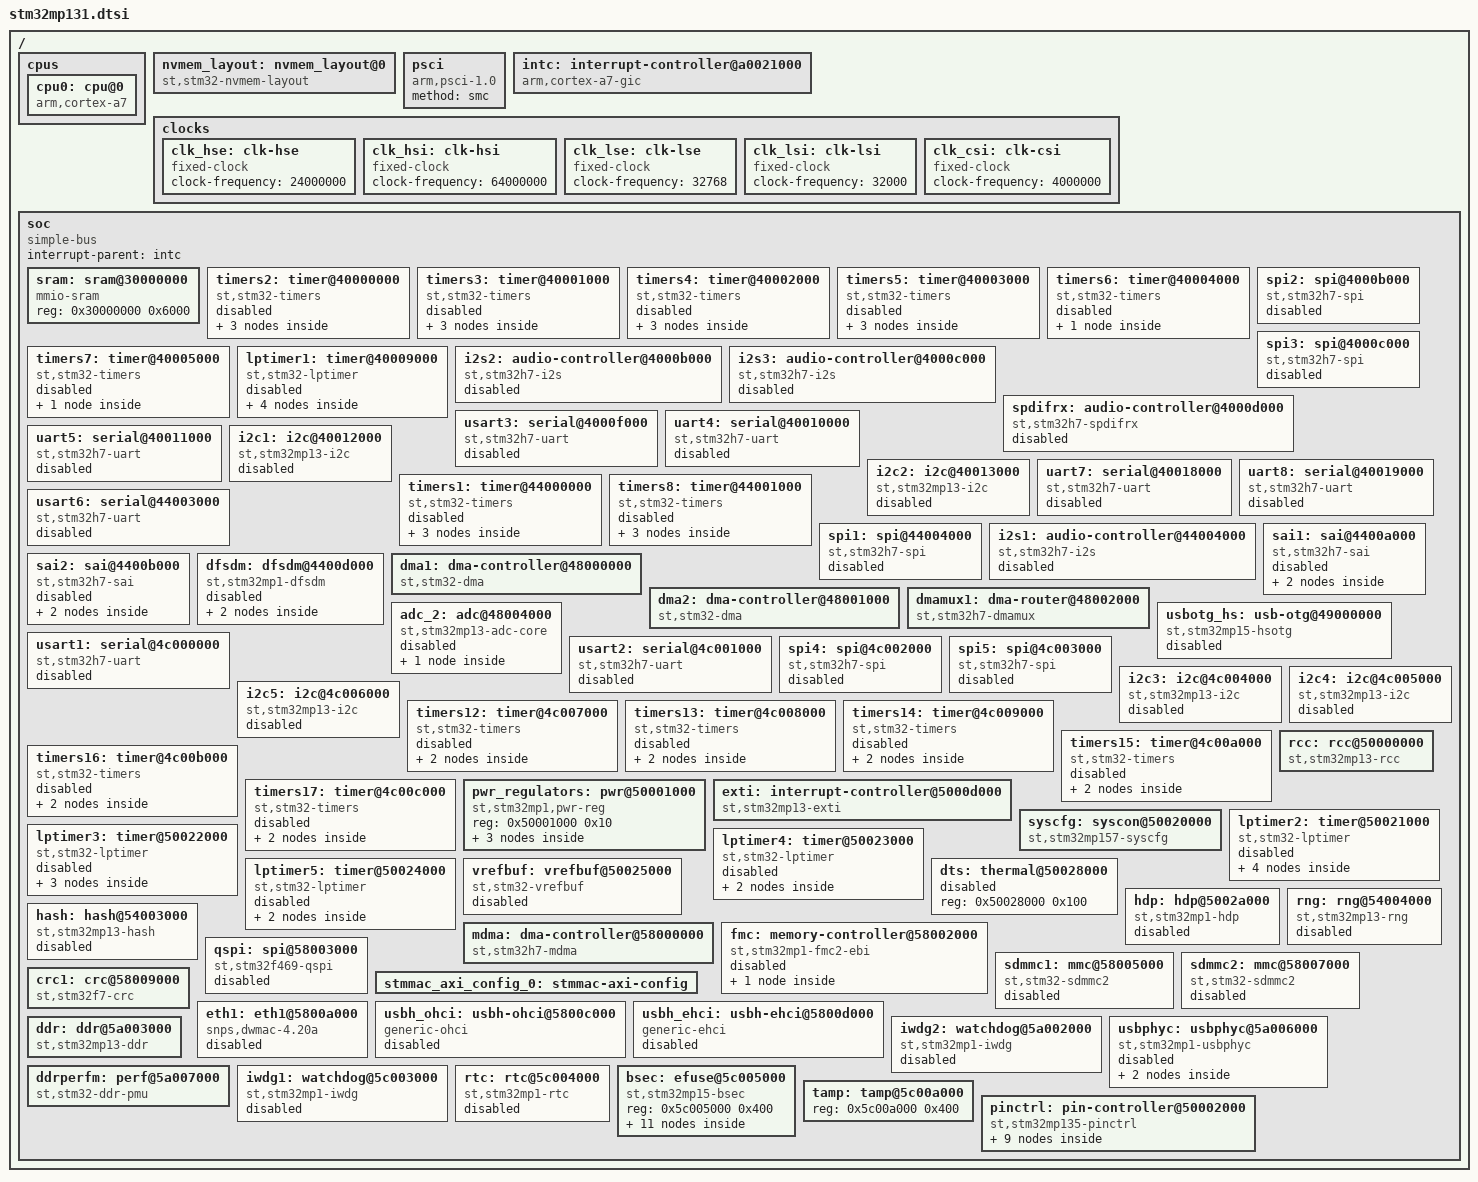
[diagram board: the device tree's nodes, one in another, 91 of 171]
// SPDX-License-Identifier: (GPL-2.0+ OR BSD-3-Clause)
/*
 * Copyright (C) STMicroelectronics 2017 - All Rights Reserved
 * Author: Ludovic Barre <ludovic.barre@st.com> for STMicroelectronics.
 */
#include <dt-bindings/interrupt-controller/arm-gic.h>
#include <dt-bindings/clock/stm32mp13-clks.h>
#include <dt-bindings/reset/stm32mp13-resets.h>

/ {
	#address-cells = <1>;
	#size-cells = <1>;

	cpus {
		#address-cells = <1>;
		#size-cells = <0>;

		cpu0: cpu@0 {
			compatible = "arm,cortex-a7";
			device_type = "cpu";
			reg = <0>;
			clocks = <&rcc CK_MPU>;
			clock-names = "cpu";
			nvmem-cells = <&part_number_otp>;
			nvmem-cell-names = "part_number";
		};
	};

	nvmem_layout: nvmem_layout@0 {
		compatible = "st,stm32-nvmem-layout";

		nvmem-cells = <&cfg0_otp>,
			      <&part_number_otp>,
			      <&monotonic_otp>,
			      <&nand_otp>,
			      <&nand2_otp>,
			      <&uid_otp>,
			      <&hw2_otp>,
			      <&pkh_otp>;

		nvmem-cell-names = "cfg0_otp",
				   "part_number_otp",
				   "monotonic_otp",
				   "nand_otp",
				   "nand2_otp",
				   "uid_otp",
				   "hw2_otp",
				   "pkh_otp";
	};

	psci {
		compatible = "arm,psci-1.0";
		method = "smc";
	};

	intc: interrupt-controller@a0021000 {
		compatible = "arm,cortex-a7-gic";
		#interrupt-cells = <3>;
		interrupt-controller;
		reg = <0xa0021000 0x1000>,
		      <0xa0022000 0x2000>;
	};

	clocks {
		clk_hse: clk-hse {
			#clock-cells = <0>;
			compatible = "fixed-clock";
			clock-frequency = <24000000>;
		};

		clk_hsi: clk-hsi {
			#clock-cells = <0>;
			compatible = "fixed-clock";
			clock-frequency = <64000000>;
		};

		clk_lse: clk-lse {
			#clock-cells = <0>;
			compatible = "fixed-clock";
			clock-frequency = <32768>;
		};

		clk_lsi: clk-lsi {
			#clock-cells = <0>;
			compatible = "fixed-clock";
			clock-frequency = <32000>;
		};

		clk_csi: clk-csi {
			#clock-cells = <0>;
			compatible = "fixed-clock";
			clock-frequency = <4000000>;
		};
	};

	soc {
		compatible = "simple-bus";
		#address-cells = <1>;
		#size-cells = <1>;
		interrupt-parent = <&intc>;
		ranges;

		sram: sram@30000000 {
			compatible = "mmio-sram";
			reg = <0x30000000 0x6000>;
			#address-cells = <1>;
			#size-cells = <1>;
			ranges = <0 0x30000000 0x6000>;
		};

		timers2: timer@40000000 {
			#address-cells = <1>;
			#size-cells = <0>;
			compatible = "st,stm32-timers";
			reg = <0x40000000 0x400>;
			interrupts = <GIC_SPI 29 IRQ_TYPE_LEVEL_HIGH>;
			clocks = <&rcc TIM2_K>;
			clock-names = "int";
			status = "disabled";

			pwm {
				compatible = "st,stm32-pwm";
				#pwm-cells = <3>;
				status = "disabled";
			};

			timer@1 {
				compatible = "st,stm32h7-timer-trigger";
				reg = <1>;
				status = "disabled";
			};

			counter {
				compatible = "st,stm32-timer-counter";
				status = "disabled";
			};
		};

		timers3: timer@40001000 {
			#address-cells = <1>;
			#size-cells = <0>;
			compatible = "st,stm32-timers";
			reg = <0x40001000 0x400>;
			interrupts = <GIC_SPI 30 IRQ_TYPE_LEVEL_HIGH>;
			clocks = <&rcc TIM3_K>;
			clock-names = "int";
			status = "disabled";

			pwm {
				compatible = "st,stm32-pwm";
				#pwm-cells = <3>;
				status = "disabled";
			};

			timer@2 {
				compatible = "st,stm32h7-timer-trigger";
				reg = <2>;
				status = "disabled";
			};

			counter {
				compatible = "st,stm32-timer-counter";
				status = "disabled";
			};
		};

		timers4: timer@40002000 {
			#address-cells = <1>;
			#size-cells = <0>;
			compatible = "st,stm32-timers";
			reg = <0x40002000 0x400>;
			interrupts = <GIC_SPI 31 IRQ_TYPE_LEVEL_HIGH>;
			clocks = <&rcc TIM4_K>;
			clock-names = "int";
			status = "disabled";

			pwm {
				compatible = "st,stm32-pwm";
				#pwm-cells = <3>;
				status = "disabled";
			};

			timer@3 {
				compatible = "st,stm32h7-timer-trigger";
				reg = <3>;
				status = "disabled";
			};

			counter {
				compatible = "st,stm32-timer-counter";
				status = "disabled";
			};
		};

		timers5: timer@40003000 {
			#address-cells = <1>;
			#size-cells = <0>;
			compatible = "st,stm32-timers";
			reg = <0x40003000 0x400>;
			interrupts = <GIC_SPI 51 IRQ_TYPE_LEVEL_HIGH>;
			clocks = <&rcc TIM5_K>;
			clock-names = "int";
			status = "disabled";

			pwm {
				compatible = "st,stm32-pwm";
				#pwm-cells = <3>;
				status = "disabled";
			};

			timer@4 {
				compatible = "st,stm32h7-timer-trigger";
				reg = <4>;
				status = "disabled";
			};

			counter {
				compatible = "st,stm32-timer-counter";
				status = "disabled";
			};
		};

		timers6: timer@40004000 {
			#address-cells = <1>;
			#size-cells = <0>;
			compatible = "st,stm32-timers";
			reg = <0x40004000 0x400>;
			interrupts = <GIC_SPI 55 IRQ_TYPE_LEVEL_HIGH>;
			clocks = <&rcc TIM6_K>;
			clock-names = "int";
			status = "disabled";

			timer@5 {
				compatible = "st,stm32h7-timer-trigger";
				reg = <5>;
				status = "disabled";
			};
		};

		timers7: timer@40005000 {
			#address-cells = <1>;
			#size-cells = <0>;
			compatible = "st,stm32-timers";
			reg = <0x40005000 0x400>;
			interrupts = <GIC_SPI 56 IRQ_TYPE_LEVEL_HIGH>;
			clocks = <&rcc TIM7_K>;
			clock-names = "int";
			status = "disabled";

			timer@6 {
				compatible = "st,stm32h7-timer-trigger";
				reg = <6>;
				status = "disabled";
			};
		};

		lptimer1: timer@40009000 {
			#address-cells = <1>;
			#size-cells = <0>;
			compatible = "st,stm32-lptimer";
			reg = <0x40009000 0x400>;
			interrupts-extended = <&exti 47 IRQ_TYPE_LEVEL_HIGH>;
			clocks = <&rcc LPTIM1_K>;
			clock-names = "mux";
			status = "disabled";

			pwm {
				compatible = "st,stm32-pwm-lp";
				#pwm-cells = <3>;
				status = "disabled";
			};

			trigger@0 {
				compatible = "st,stm32-lptimer-trigger";
				reg = <0>;
				status = "disabled";
			};

			counter {
				compatible = "st,stm32-lptimer-counter";
				status = "disabled";
			};

			timer {
				compatible = "st,stm32-lptimer-timer";
				status = "disabled";
			};
		};

		spi2: spi@4000b000 {
			#address-cells = <1>;
			#size-cells = <0>;
			compatible = "st,stm32h7-spi";
			reg = <0x4000b000 0x400>;
			interrupts = <GIC_SPI 37 IRQ_TYPE_LEVEL_HIGH>;
			clocks = <&rcc SPI2_K>;
			resets = <&rcc SPI2_R>;
			status = "disabled";
		};

		i2s2: audio-controller@4000b000 {
			compatible = "st,stm32h7-i2s";
			#sound-dai-cells = <0>;
			reg = <0x4000b000 0x400>;
			interrupts = <GIC_SPI 37 IRQ_TYPE_LEVEL_HIGH>;
			status = "disabled";
		};

		spi3: spi@4000c000 {
			#address-cells = <1>;
			#size-cells = <0>;
			compatible = "st,stm32h7-spi";
			reg = <0x4000c000 0x400>;
			interrupts = <GIC_SPI 52 IRQ_TYPE_LEVEL_HIGH>;
			clocks = <&rcc SPI3_K>;
			resets = <&rcc SPI3_R>;
			status = "disabled";
		};

		i2s3: audio-controller@4000c000 {
			compatible = "st,stm32h7-i2s";
			#sound-dai-cells = <0>;
			reg = <0x4000c000 0x400>;
			interrupts = <GIC_SPI 52 IRQ_TYPE_LEVEL_HIGH>;
			status = "disabled";
		};

		spdifrx: audio-controller@4000d000 {
			compatible = "st,stm32h7-spdifrx";
			#sound-dai-cells = <0>;
			reg = <0x4000d000 0x400>;
			clocks = <&rcc SPDIF_K>;
			clock-names = "kclk";
			interrupts = <GIC_SPI 95 IRQ_TYPE_LEVEL_HIGH>;
			status = "disabled";
		};

		usart3: serial@4000f000 {
			compatible = "st,stm32h7-uart";
			reg = <0x4000f000 0x400>;
			interrupts = <GIC_SPI 40 IRQ_TYPE_LEVEL_HIGH>;
			clocks = <&rcc USART3_K>;
			resets = <&rcc USART3_R>;
			status = "disabled";
		};

		uart4: serial@40010000 {
			compatible = "st,stm32h7-uart";
			reg = <0x40010000 0x400>;
			interrupts = <GIC_SPI 53 IRQ_TYPE_LEVEL_HIGH>;
			clocks = <&rcc UART4_K>;
			resets = <&rcc UART4_R>;
			status = "disabled";
		};

		uart5: serial@40011000 {
			compatible = "st,stm32h7-uart";
			reg = <0x40011000 0x400>;
			interrupts = <GIC_SPI 54 IRQ_TYPE_LEVEL_HIGH>;
			clocks = <&rcc UART5_K>;
			resets = <&rcc UART5_R>;
			status = "disabled";
		};

		i2c1: i2c@40012000 {
			compatible = "st,stm32mp13-i2c";
			reg = <0x40012000 0x400>;
			interrupt-names = "event", "error";
			interrupts-extended = <&exti 21 IRQ_TYPE_LEVEL_HIGH>,
					      <&intc GIC_SPI 33 IRQ_TYPE_LEVEL_HIGH>;
			clocks = <&rcc I2C1_K>;
			resets = <&rcc I2C1_R>;
			#address-cells = <1>;
			#size-cells = <0>;
			st,syscfg-fmp = <&syscfg 0x4 0x1>;
			i2c-analog-filter;
			status = "disabled";
		};

		i2c2: i2c@40013000 {
			compatible = "st,stm32mp13-i2c";
			reg = <0x40013000 0x400>;
			interrupt-names = "event", "error";
			interrupts-extended = <&exti 22 IRQ_TYPE_LEVEL_HIGH>,
					      <&intc GIC_SPI 35 IRQ_TYPE_LEVEL_HIGH>;
			clocks = <&rcc I2C2_K>;
			resets = <&rcc I2C2_R>;
			#address-cells = <1>;
			#size-cells = <0>;
			st,syscfg-fmp = <&syscfg 0x4 0x2>;
			i2c-analog-filter;
			status = "disabled";
		};

		uart7: serial@40018000 {
			compatible = "st,stm32h7-uart";
			reg = <0x40018000 0x400>;
			interrupts = <GIC_SPI 83 IRQ_TYPE_LEVEL_HIGH>;
			clocks = <&rcc UART7_K>;
			resets = <&rcc UART7_R>;
			status = "disabled";
		};

		uart8: serial@40019000 {
			compatible = "st,stm32h7-uart";
			reg = <0x40019000 0x400>;
			interrupts = <GIC_SPI 84 IRQ_TYPE_LEVEL_HIGH>;
			clocks = <&rcc UART8_K>;
			resets = <&rcc UART8_R>;
			status = "disabled";
		};

		timers1: timer@44000000 {
			#address-cells = <1>;
			#size-cells = <0>;
			compatible = "st,stm32-timers";
			reg = <0x44000000 0x400>;
			interrupts = <GIC_SPI 25 IRQ_TYPE_LEVEL_HIGH>,
				     <GIC_SPI 26 IRQ_TYPE_LEVEL_HIGH>,
				     <GIC_SPI 27 IRQ_TYPE_LEVEL_HIGH>,
				     <GIC_SPI 28 IRQ_TYPE_LEVEL_HIGH>;
			clocks = <&rcc TIM1_K>;
			clock-names = "int";
			status = "disabled";

			pwm {
				compatible = "st,stm32-pwm";
				#pwm-cells = <3>;
				status = "disabled";
			};

			timer@0 {
				compatible = "st,stm32h7-timer-trigger";
				reg = <0>;
				status = "disabled";
			};

			counter {
				compatible = "st,stm32-timer-counter";
				status = "disabled";
			};
		};

		timers8: timer@44001000 {
			#address-cells = <1>;
			#size-cells = <0>;
			compatible = "st,stm32-timers";
			reg = <0x44001000 0x400>;
			interrupts = <GIC_SPI 44 IRQ_TYPE_LEVEL_HIGH>,
				     <GIC_SPI 45 IRQ_TYPE_LEVEL_HIGH>,
				     <GIC_SPI 46 IRQ_TYPE_LEVEL_HIGH>,
				     <GIC_SPI 47 IRQ_TYPE_LEVEL_HIGH>;
			clocks = <&rcc TIM8_K>;
			clock-names = "int";
			status = "disabled";

			pwm {
				compatible = "st,stm32-pwm";
				#pwm-cells = <3>;
				status = "disabled";
			};

			timer@7 {
				compatible = "st,stm32h7-timer-trigger";
				reg = <7>;
				status = "disabled";
			};

			counter {
				compatible = "st,stm32-timer-counter";
				status = "disabled";
			};
		};

		usart6: serial@44003000 {
			compatible = "st,stm32h7-uart";
			reg = <0x44003000 0x400>;
			interrupts = <GIC_SPI 72 IRQ_TYPE_LEVEL_HIGH>;
			clocks = <&rcc USART6_K>;
			resets = <&rcc USART6_R>;
			status = "disabled";
		};

		spi1: spi@44004000 {
			#address-cells = <1>;
			#size-cells = <0>;
			compatible = "st,stm32h7-spi";
			reg = <0x44004000 0x400>;
			interrupts = <GIC_SPI 36 IRQ_TYPE_LEVEL_HIGH>;
			clocks = <&rcc SPI1_K>;
			resets = <&rcc SPI1_R>;
			status = "disabled";
		};

		i2s1: audio-controller@44004000 {
			compatible = "st,stm32h7-i2s";
			#sound-dai-cells = <0>;
			reg = <0x44004000 0x400>;
			interrupts = <GIC_SPI 36 IRQ_TYPE_LEVEL_HIGH>;
			status = "disabled";
		};

		sai1: sai@4400a000 {
			compatible = "st,stm32h7-sai";
			#address-cells = <1>;
			#size-cells = <1>;
			ranges = <0 0x4400a000 0x400>;
			reg = <0x4400a000 0x4>, <0x4400a3f0 0x10>;
			interrupts = <GIC_SPI 87 IRQ_TYPE_LEVEL_HIGH>;
			resets = <&rcc SAI1_R>;
			status = "disabled";

			sai1a: audio-controller@4400a004 {
				#sound-dai-cells = <0>;

				compatible = "st,stm32-sai-sub-a";
				reg = <0x4 0x1c>;
				clocks = <&rcc SAI1_K>;
				clock-names = "sai_ck";
				status = "disabled";
			};

			sai1b: audio-controller@4400a024 {
				#sound-dai-cells = <0>;
				compatible = "st,stm32-sai-sub-b";
				reg = <0x24 0x1c>;
				clocks = <&rcc SAI1_K>;
				clock-names = "sai_ck";
				status = "disabled";
			};
		};

		sai2: sai@4400b000 {
			compatible = "st,stm32h7-sai";
			#address-cells = <1>;
			#size-cells = <1>;
			ranges = <0 0x4400b000 0x400>;
			reg = <0x4400b000 0x4>, <0x4400b3f0 0x10>;
			interrupts = <GIC_SPI 90 IRQ_TYPE_LEVEL_HIGH>;
			resets = <&rcc SAI2_R>;
			status = "disabled";

			sai2a: audio-controller@4400b004 {
				#sound-dai-cells = <0>;
				compatible = "st,stm32-sai-sub-a";
				reg = <0x4 0x1c>;
				clocks = <&rcc SAI2_K>;
				clock-names = "sai_ck";
				status = "disabled";
			};

			sai2b: audio-controller@4400b024 {
				#sound-dai-cells = <0>;
				compatible = "st,stm32-sai-sub-b";
				reg = <0x24 0x1c>;
				clocks = <&rcc SAI2_K>;
				clock-names = "sai_ck";
				status = "disabled";
			};
		};

		dfsdm: dfsdm@4400d000 {
			compatible = "st,stm32mp1-dfsdm";
			reg = <0x4400d000 0x800>;
			clocks = <&rcc DFSDM_K>;
			clock-names = "dfsdm";
			#address-cells = <1>;
			#size-cells = <0>;
			status = "disabled";

			dfsdm0: filter@0 {
				compatible = "st,stm32-dfsdm-adc";
				#io-channel-cells = <1>;
				reg = <0>;
				interrupts = <GIC_SPI 140 IRQ_TYPE_LEVEL_HIGH>;
				status = "disabled";
			};

			dfsdm1: filter@1 {
				compatible = "st,stm32-dfsdm-adc";
				#io-channel-cells = <1>;
				reg = <1>;
				interrupts = <GIC_SPI 141 IRQ_TYPE_LEVEL_HIGH>;
				status = "disabled";
			};
		};

		dma1: dma-controller@48000000 {
			compatible = "st,stm32-dma";
			reg = <0x48000000 0x400>;
			interrupts = <GIC_SPI 11 IRQ_TYPE_LEVEL_HIGH>,
				     <GIC_SPI 12 IRQ_TYPE_LEVEL_HIGH>,
				     <GIC_SPI 13 IRQ_TYPE_LEVEL_HIGH>,
				     <GIC_SPI 14 IRQ_TYPE_LEVEL_HIGH>,
				     <GIC_SPI 15 IRQ_TYPE_LEVEL_HIGH>,
				     <GIC_SPI 16 IRQ_TYPE_LEVEL_HIGH>,
				     <GIC_SPI 17 IRQ_TYPE_LEVEL_HIGH>,
				     <GIC_SPI 48 IRQ_TYPE_LEVEL_HIGH>;
			clocks = <&rcc DMA1>;
			resets = <&rcc DMA1_R>;
			#dma-cells = <4>;
			st,mem2mem;
			dma-requests = <8>;
		};

		dma2: dma-controller@48001000 {
			compatible = "st,stm32-dma";
			reg = <0x48001000 0x400>;
			interrupts = <GIC_SPI 57 IRQ_TYPE_LEVEL_HIGH>,
				     <GIC_SPI 58 IRQ_TYPE_LEVEL_HIGH>,
				     <GIC_SPI 59 IRQ_TYPE_LEVEL_HIGH>,
				     <GIC_SPI 60 IRQ_TYPE_LEVEL_HIGH>,
				     <GIC_SPI 61 IRQ_TYPE_LEVEL_HIGH>,
				     <GIC_SPI 69 IRQ_TYPE_LEVEL_HIGH>,
				     <GIC_SPI 70 IRQ_TYPE_LEVEL_HIGH>,
				     <GIC_SPI 71 IRQ_TYPE_LEVEL_HIGH>;
			clocks = <&rcc DMA2>;
			resets = <&rcc DMA2_R>;
			#dma-cells = <4>;
			st,mem2mem;
			dma-requests = <8>;
		};

		dmamux1: dma-router@48002000 {
			compatible = "st,stm32h7-dmamux";
			reg = <0x48002000 0x40>;
			clocks = <&rcc DMAMUX1>;
			resets = <&rcc DMAMUX1_R>;
			#dma-cells = <3>;
			dma-masters = <&dma1 &dma2>;
			dma-requests = <128>;
			dma-channels = <16>;
		};

		adc_2: adc@48004000 {
			reg = <0x48004000 0x400>;
			compatible = "st,stm32mp13-adc-core";
			interrupts = <GIC_SPI 19 IRQ_TYPE_LEVEL_HIGH>;
			clocks = <&rcc ADC2>, <&rcc ADC2_K>;
			clock-names = "bus", "adc";
			interrupt-controller;
			#interrupt-cells = <1>;
			#address-cells = <1>;
			#size-cells = <0>;
			status = "disabled";

			adc2: adc@0 {
				compatible = "st,stm32mp13-adc";
				#io-channel-cells = <1>;
				reg = <0x0>;
				interrupt-parent = <&adc_2>;
				interrupts = <0>;
				status = "disabled";
			};
		};

		usbotg_hs: usb-otg@49000000 {
			compatible = "st,stm32mp15-hsotg", "snps,dwc2";
			reg = <0x49000000 0x40000>;
			clocks = <&rcc USBO_K>;
			clock-names = "otg";
			resets = <&rcc USBO_R>;
			reset-names = "dwc2";
			interrupts = <GIC_SPI 96 IRQ_TYPE_LEVEL_HIGH>;
			g-rx-fifo-size = <512>;
			g-np-tx-fifo-size = <32>;
			g-tx-fifo-size = <256 16 16 16 16 16 16 16>;
			dr_mode = "otg";
			usb33d-supply = <&usb33>;
			status = "disabled";
		};

		usart1: serial@4c000000 {
			compatible = "st,stm32h7-uart";
			reg = <0x4c000000 0x400>;
			interrupts = <GIC_SPI 38 IRQ_TYPE_LEVEL_HIGH>;
			clocks = <&rcc USART1_K>;
			resets = <&rcc USART1_R>;
			status = "disabled";
		};

		usart2: serial@4c001000 {
			compatible = "st,stm32h7-uart";
			reg = <0x4c001000 0x400>;
			interrupts = <GIC_SPI 39 IRQ_TYPE_LEVEL_HIGH>;
			clocks = <&rcc USART2_K>;
			resets = <&rcc USART2_R>;
			status = "disabled";
		};

		spi4: spi@4c002000 {
			#address-cells = <1>;
			#size-cells = <0>;
			compatible = "st,stm32h7-spi";
			reg = <0x4c002000 0x400>;
			interrupts = <GIC_SPI 85 IRQ_TYPE_LEVEL_HIGH>;
			clocks = <&rcc SPI4_K>;
			resets = <&rcc SPI4_R>;
			status = "disabled";
		};

		spi5: spi@4c003000 {
			#address-cells = <1>;
			#size-cells = <0>;
			compatible = "st,stm32h7-spi";
			reg = <0x4c003000 0x400>;
			interrupts = <GIC_SPI 86 IRQ_TYPE_LEVEL_HIGH>;
			clocks = <&rcc SPI5_K>;
			resets = <&rcc SPI5_R>;
			status = "disabled";
		};

		i2c3: i2c@4c004000 {
			compatible = "st,stm32mp13-i2c";
			reg = <0x4c004000 0x400>;
			interrupt-names = "event", "error";
			interrupts-extended = <&exti 23 IRQ_TYPE_LEVEL_HIGH>,
					      <&intc GIC_SPI 74 IRQ_TYPE_LEVEL_HIGH>;
			clocks = <&rcc I2C3_K>;
			resets = <&rcc I2C3_R>;
			#address-cells = <1>;
			#size-cells = <0>;
			st,syscfg-fmp = <&syscfg 0x4 0x4>;
			i2c-analog-filter;
			status = "disabled";
		};

		i2c4: i2c@4c005000 {
			compatible = "st,stm32mp13-i2c";
			reg = <0x4c005000 0x400>;
			interrupt-names = "event", "error";
			interrupts-extended = <&exti 24 IRQ_TYPE_LEVEL_HIGH>,
					      <&intc GIC_SPI 94 IRQ_TYPE_LEVEL_HIGH>;
			clocks = <&rcc I2C4_K>;
			resets = <&rcc I2C4_R>;
			#address-cells = <1>;
			#size-cells = <0>;
			st,syscfg-fmp = <&syscfg 0x4 0x8>;
			i2c-analog-filter;
			status = "disabled";
		};

		i2c5: i2c@4c006000 {
			compatible = "st,stm32mp13-i2c";
			reg = <0x4c006000 0x400>;
			interrupt-names = "event", "error";
			interrupts-extended = <&exti 25 IRQ_TYPE_LEVEL_HIGH>,
					      <&intc GIC_SPI 115 IRQ_TYPE_LEVEL_HIGH>;
			clocks = <&rcc I2C5_K>;
			resets = <&rcc I2C5_R>;
			#address-cells = <1>;
			#size-cells = <0>;
			st,syscfg-fmp = <&syscfg 0x4 0x10>;
			i2c-analog-filter;
			status = "disabled";
		};

		timers12: timer@4c007000 {
			#address-cells = <1>;
			#size-cells = <0>;
			compatible = "st,stm32-timers";
			reg = <0x4c007000 0x400>;
			interrupts = <GIC_SPI 104 IRQ_TYPE_LEVEL_HIGH>;
			clocks = <&rcc TIM12_K>;
			clock-names = "int";
			status = "disabled";

			pwm {
				compatible = "st,stm32-pwm";
				#pwm-cells = <3>;
				status = "disabled";
			};

			timer@11 {
				compatible = "st,stm32h7-timer-trigger";
				reg = <11>;
				status = "disabled";
			};
		};

		timers13: timer@4c008000 {
			#address-cells = <1>;
			#size-cells = <0>;
			compatible = "st,stm32-timers";
			reg = <0x4c008000 0x400>;
			interrupts = <GIC_SPI 111 IRQ_TYPE_LEVEL_HIGH>;
			clocks = <&rcc TIM13_K>;
			clock-names = "int";
			status = "disabled";

			pwm {
				compatible = "st,stm32-pwm";
				#pwm-cells = <3>;
				status = "disabled";
			};

			timer@12 {
				compatible = "st,stm32h7-timer-trigger";
				reg = <12>;
				status = "disabled";
			};
		};

		timers14: timer@4c009000 {
			#address-cells = <1>;
			#size-cells = <0>;
			compatible = "st,stm32-timers";
			reg = <0x4c009000 0x400>;
			interrupts = <GIC_SPI 112 IRQ_TYPE_LEVEL_HIGH>;
			clocks = <&rcc TIM14_K>;
			clock-names = "int";
			status = "disabled";

			pwm {
				compatible = "st,stm32-pwm";
				#pwm-cells = <3>;
				status = "disabled";
			};

			timer@13 {
				compatible = "st,stm32h7-timer-trigger";
				reg = <13>;
				status = "disabled";
			};
		};

		timers15: timer@4c00a000 {
			#address-cells = <1>;
			#size-cells = <0>;
			compatible = "st,stm32-timers";
			reg = <0x4c00a000 0x400>;
			interrupts = <GIC_SPI 101 IRQ_TYPE_LEVEL_HIGH>;
			clocks = <&rcc TIM15_K>;
			clock-names = "int";
			status = "disabled";

			pwm {
				compatible = "st,stm32-pwm";
				#pwm-cells = <3>;
				status = "disabled";
			};

			timer@14 {
				compatible = "st,stm32h7-timer-trigger";
				reg = <14>;
				status = "disabled";
			};
		};

		timers16: timer@4c00b000 {
			#address-cells = <1>;
			#size-cells = <0>;
			compatible = "st,stm32-timers";
			reg = <0x4c00b000 0x400>;
			interrupts = <GIC_SPI 102 IRQ_TYPE_LEVEL_HIGH>;
			clocks = <&rcc TIM16_K>;
			clock-names = "int";
			status = "disabled";

			pwm {
				compatible = "st,stm32-pwm";
				#pwm-cells = <3>;
				status = "disabled";
			};

			timer@15 {
				compatible = "st,stm32h7-timer-trigger";
				reg = <15>;
				status = "disabled";
			};
		};

		timers17: timer@4c00c000 {
			#address-cells = <1>;
			#size-cells = <0>;
			compatible = "st,stm32-timers";
			reg = <0x4c00c000 0x400>;
			clocks = <&rcc TIM17_K>;
			clock-names = "int";
			status = "disabled";

			pwm {
				compatible = "st,stm32-pwm";
				#pwm-cells = <3>;
				status = "disabled";
			};

			timer@16 {
				compatible = "st,stm32h7-timer-trigger";
				reg = <16>;
				status = "disabled";
			};
		};

		rcc: rcc@50000000 {
			compatible = "st,stm32mp13-rcc", "syscon";
			reg = <0x50000000 0x1000>;
			#address-cells = <1>;
			#size-cells = <0>;
			#clock-cells = <1>;
			#reset-cells = <1>;
			interrupts = <GIC_SPI 5 IRQ_TYPE_LEVEL_HIGH>;
			secure-interrupts = <GIC_SPI 122 IRQ_TYPE_LEVEL_HIGH>;
			secure-interrupt-names = "wakeup";
		};

		pwr_regulators: pwr@50001000 {
			compatible = "st,stm32mp1,pwr-reg";
			reg = <0x50001000 0x10>;

			reg11: reg11 {
				regulator-name = "reg11";
				regulator-min-microvolt = <1100000>;
				regulator-max-microvolt = <1100000>;
			};

			reg18: reg18 {
				regulator-name = "reg18";
				regulator-min-microvolt = <1800000>;
				regulator-max-microvolt = <1800000>;
			};

			usb33: usb33 {
				regulator-name = "usb33";
				regulator-min-microvolt = <3300000>;
				regulator-max-microvolt = <3300000>;
			};
		};

		exti: interrupt-controller@5000d000 {
			compatible = "st,stm32mp13-exti", "syscon";
			interrupt-controller;
			#interrupt-cells = <2>;
			reg = <0x5000d000 0x400>;
		};

		syscfg: syscon@50020000 {
			compatible = "st,stm32mp157-syscfg", "syscon";
			reg = <0x50020000 0x400>;
			clocks = <&rcc SYSCFG>;
		};

		lptimer2: timer@50021000 {
			#address-cells = <1>;
			#size-cells = <0>;
			compatible = "st,stm32-lptimer";
			reg = <0x50021000 0x400>;
			interrupts-extended = <&exti 48 IRQ_TYPE_LEVEL_HIGH>;
			clocks = <&rcc LPTIM2_K>;
			clock-names = "mux";
			status = "disabled";

			pwm {
				compatible = "st,stm32-pwm-lp";
				#pwm-cells = <3>;
				status = "disabled";
			};

			trigger@1 {
				compatible = "st,stm32-lptimer-trigger";
				reg = <1>;
				status = "disabled";
			};

			counter {
				compatible = "st,stm32-lptimer-counter";
				status = "disabled";
			};

			timer {
				compatible = "st,stm32-lptimer-timer";
				status = "disabled";
			};
		};

		lptimer3: timer@50022000 {
			#address-cells = <1>;
			#size-cells = <0>;
			compatible = "st,stm32-lptimer";
			reg = <0x50022000 0x400>;
			interrupts = <GIC_SPI 117 IRQ_TYPE_LEVEL_HIGH>;
			clocks = <&rcc LPTIM3_K>;
			clock-names = "mux";
			status = "disabled";

			pwm {
				compatible = "st,stm32-pwm-lp";
				#pwm-cells = <3>;
				status = "disabled";
			};

			trigger@2 {
				compatible = "st,stm32-lptimer-trigger";
				reg = <2>;
				status = "disabled";
			};

			timer {
				compatible = "st,stm32-lptimer-timer";
				status = "disabled";
			};
		};

		lptimer4: timer@50023000 {
			compatible = "st,stm32-lptimer";
			reg = <0x50023000 0x400>;
			interrupts-extended = <&exti 52 IRQ_TYPE_LEVEL_HIGH>;
			clocks = <&rcc LPTIM4_K>;
			clock-names = "mux";
			status = "disabled";

			pwm {
				compatible = "st,stm32-pwm-lp";
				#pwm-cells = <3>;
				status = "disabled";
			};

			timer {
				compatible = "st,stm32-lptimer-timer";
				status = "disabled";
			};
		};

		lptimer5: timer@50024000 {
			compatible = "st,stm32-lptimer";
			reg = <0x50024000 0x400>;
			interrupts-extended = <&exti 53 IRQ_TYPE_LEVEL_HIGH>;
			clocks = <&rcc LPTIM5_K>;
			clock-names = "mux";
			status = "disabled";

			pwm {
				compatible = "st,stm32-pwm-lp";
				#pwm-cells = <3>;
				status = "disabled";
			};

			timer {
				compatible = "st,stm32-lptimer-timer";
				status = "disabled";
			};
		};

		vrefbuf: vrefbuf@50025000 {
			compatible = "st,stm32-vrefbuf";
			reg = <0x50025000 0x8>;
			regulator-min-microvolt = <1500000>;
			regulator-max-microvolt = <2500000>;
			clocks = <&rcc VREF>;
			status = "disabled";
		};

		dts: thermal@50028000 {
			reg = <0x50028000 0x100>;
			status = "disabled";
		};

		hdp: hdp@5002a000 {
			compatible = "st,stm32mp1-hdp";
			reg = <0x5002a000 0x400>;
			clocks = <&rcc HDP>;
			clock-names = "hdp";
			status = "disabled";
		};

		hash: hash@54003000 {
			compatible = "st,stm32mp13-hash";
			reg = <0x54003000 0x400>;
			clocks = <&rcc HASH1>;
			resets = <&rcc HASH1_R>;
			status = "disabled";
		};

		rng: rng@54004000 {
			compatible = "st,stm32mp13-rng";
			reg = <0x54004000 0x400>;
			clocks = <&rcc RNG1_K>;
			resets = <&rcc RNG1_R>;
			status = "disabled";
		};

		mdma: dma-controller@58000000 {
			compatible = "st,stm32h7-mdma";
			reg = <0x58000000 0x1000>;
			interrupts = <GIC_SPI 107 IRQ_TYPE_LEVEL_HIGH>;
			clocks = <&rcc MDMA>;
			#dma-cells = <6>;
			dma-channels = <32>;
			dma-requests = <48>;
		};

		fmc: memory-controller@58002000 {
			#address-cells = <2>;
			#size-cells = <1>;
			compatible = "st,stm32mp1-fmc2-ebi";
			reg = <0x58002000 0x1000>;
			clocks = <&rcc FMC_K>;
			resets = <&rcc FMC_R>;
			status = "disabled";

			ranges = <0 0 0x60000000 0x04000000>, /* EBI CS 1 */
				 <1 0 0x64000000 0x04000000>, /* EBI CS 2 */
				 <2 0 0x68000000 0x04000000>, /* EBI CS 3 */
				 <3 0 0x6c000000 0x04000000>, /* EBI CS 4 */
				 <4 0 0x80000000 0x10000000>; /* NAND */

			nand-controller@4,0 {
				#address-cells = <1>;
				#size-cells = <0>;
				compatible = "st,stm32mp1-fmc2-nfc";
				reg = <4 0x00000000 0x1000>,
				      <4 0x08010000 0x1000>,
				      <4 0x08020000 0x1000>,
				      <4 0x01000000 0x1000>,
				      <4 0x09010000 0x1000>,
				      <4 0x09020000 0x1000>;
				interrupts = <GIC_SPI 49 IRQ_TYPE_LEVEL_HIGH>;
				status = "disabled";
			};
		};

		qspi: spi@58003000 {
			compatible = "st,stm32f469-qspi";
			reg = <0x58003000 0x1000>, <0x70000000 0x10000000>;
			reg-names = "qspi", "qspi_mm";
			interrupts = <GIC_SPI 91 IRQ_TYPE_LEVEL_HIGH>;
			clocks = <&rcc QSPI_K>;
			resets = <&rcc QSPI_R>;
			status = "disabled";
		};

		sdmmc1: mmc@58005000 {
			compatible = "st,stm32-sdmmc2", "arm,pl18x", "arm,primecell";
			arm,primecell-periphid = <0x20253180>;
			reg = <0x58005000 0x1000>, <0x58006000 0x1000>;
			clocks = <&rcc SDMMC1_K>;
			clock-names = "apb_pclk";
			resets = <&rcc SDMMC1_R>;
			cap-sd-highspeed;
			cap-mmc-highspeed;
			max-frequency = <120000000>;
			status = "disabled";
		};

		sdmmc2: mmc@58007000 {
			compatible = "st,stm32-sdmmc2", "arm,pl18x", "arm,primecell";
			arm,primecell-periphid = <0x20253180>;
			reg = <0x58007000 0x1000>, <0x58008000 0x1000>;
			clocks = <&rcc SDMMC2_K>;
			clock-names = "apb_pclk";
			resets = <&rcc SDMMC2_R>;
			cap-sd-highspeed;
			cap-mmc-highspeed;
			max-frequency = <120000000>;
			status = "disabled";
		};

		crc1: crc@58009000 {
			compatible = "st,stm32f7-crc";
			reg = <0x58009000 0x400>;
			clocks = <&rcc CRC1>;
		};

		stmmac_axi_config_0: stmmac-axi-config {
			snps,wr_osr_lmt = <0x7>;
			snps,rd_osr_lmt = <0x7>;
			snps,blen = <0 0 0 0 16 8 4>;
		};

		eth1: eth1@5800a000 {
			compatible = "snps,dwmac-4.20a", "st,stm32mp13-dwmac";
			reg = <0x5800a000 0x2000>;
			reg-names = "stmmaceth";
			interrupts-extended = <&intc GIC_SPI 62 IRQ_TYPE_LEVEL_HIGH>;
			interrupt-names = "macirq";
			clock-names = "stmmaceth",
				      "mac-clk-tx",
				      "mac-clk-rx",
				      "ethstp";
			clocks = <&rcc ETH1MAC>,
				 <&rcc ETH1TX>,
				 <&rcc ETH1RX>,
				 <&rcc ETH1STP>;
			st,syscon = <&syscfg 0x4 0xff0000>;
			snps,mixed-burst;
			snps,pbl = <2>;
			snps,axi-config = <&stmmac_axi_config_0>;
			snps,tso;
			status = "disabled";
		};

		usbh_ohci: usbh-ohci@5800c000 {
			compatible = "generic-ohci";
			reg = <0x5800c000 0x1000>;
			clocks = <&rcc USBH>;
			resets = <&rcc USBH_R>;
			interrupts = <GIC_SPI 75 IRQ_TYPE_LEVEL_HIGH>;
			status = "disabled";
		};

		usbh_ehci: usbh-ehci@5800d000 {
			compatible = "generic-ehci";
			reg = <0x5800d000 0x1000>;
			clocks = <&rcc USBH>;
			resets = <&rcc USBH_R>;
			interrupts = <GIC_SPI 76 IRQ_TYPE_LEVEL_HIGH>;
			companion = <&usbh_ohci>;
			status = "disabled";
		};

		iwdg2: watchdog@5a002000 {
			compatible = "st,stm32mp1-iwdg";
			reg = <0x5a002000 0x400>;
			clocks = <&rcc IWDG2>, <&rcc CK_LSI>;
			clock-names = "pclk", "lsi";
			status = "disabled";
		};

		ddr: ddr@5a003000{
			compatible = "st,stm32mp13-ddr";
			reg = <0x5a003000 0x550>, <0x5a004000 0x234>;
			clocks = <&rcc AXIDCG>,
				 <&rcc DDRC1>,
				 <&rcc DDRPHYC>,
				 <&rcc DDRCAPB>,
				 <&rcc DDRPHYCAPB>;
			clock-names = "axidcg",
				      "ddrc1",
				      "ddrphyc",
				      "ddrcapb",
				      "ddrphycapb";
		};

		usbphyc: usbphyc@5a006000 {
			#address-cells = <1>;
			#size-cells = <0>;
			#clock-cells = <0>;
			compatible = "st,stm32mp1-usbphyc";
			reg = <0x5a006000 0x1000>;
			clocks = <&rcc USBPHY_K>;
			resets = <&rcc USBPHY_R>;
			vdda1v1-supply = <&reg11>;
			vdda1v8-supply = <&reg18>;
			status = "disabled";

			usbphyc_port0: usb-phy@0 {
				#phy-cells = <0>;
				reg = <0>;
			};

			usbphyc_port1: usb-phy@1 {
				#phy-cells = <1>;
				reg = <1>;
			};
		};

		ddrperfm: perf@5a007000 {
			compatible = "st,stm32-ddr-pmu";
			reg = <0x5a007000 0x400>;
			clocks = <&rcc DDRPERFM>;
			resets = <&rcc DDRPERFM_R>;
		};

		iwdg1: watchdog@5c003000 {
			compatible = "st,stm32mp1-iwdg";
			reg = <0x5c003000 0x400>;
			interrupts = <GIC_SPI 126 IRQ_TYPE_LEVEL_HIGH>;
			clocks = <&rcc IWDG1>, <&rcc CK_LSI>;
			clock-names = "pclk", "lsi";
			status = "disabled";
		};

		rtc: rtc@5c004000 {
			compatible = "st,stm32mp1-rtc";
			reg = <0x5c004000 0x400>;
			clocks = <&rcc RTCAPB>, <&rcc RTC>;
			clock-names = "pclk", "rtc_ck";
			interrupts-extended = <&exti 19 IRQ_TYPE_LEVEL_HIGH>;
			status = "disabled";
		};

		bsec: efuse@5c005000 {
			compatible = "st,stm32mp15-bsec";
			reg = <0x5c005000 0x400>;
			#address-cells = <1>;
			#size-cells = <1>;

			cfg0_otp: cfg0_otp@0 {
				reg = <0x0 0x2>;
			};
			part_number_otp: part_number_otp@4 {
				reg = <0x4 0x2>;
			};
			monotonic_otp: monotonic_otp@10 {
				reg = <0x10 0x4>;
			};
			nand_otp: cfg9_otp@24 {
				reg = <0x24 0x4>;
			};
			nand2_otp: cfg10_otp@28 {
				reg = <0x28 0x4>;
			};
			uid_otp: uid_otp@34 {
				reg = <0x34 0xc>;
			};
			hw2_otp: hw2_otp@48 {
				reg = <0x48 0x4>;
			};
			ts_cal1: calib@5c {
				reg = <0x5c 0x2>;
			};
			ts_cal2: calib@5e {
				reg = <0x5e 0x2>;
			};
			pkh_otp: pkh_otp@60 {
				reg = <0x60 0x20>;
			};
			mac_addr: mac_addr@e4 {
				reg = <0xe4 0xc>;
				st,non-secure-otp;
			};
		};

		tamp: tamp@5c00a000 {
			reg = <0x5c00a000 0x400>;
		};

		/*
		 * Break node order to solve dependency probe issue between
		 * pinctrl and exti.
		 */
		pinctrl: pin-controller@50002000 {
			#address-cells = <1>;
			#size-cells = <1>;
			compatible = "st,stm32mp135-pinctrl";
			ranges = <0 0x50002000 0x8400>;
			interrupt-parent = <&exti>;
			st,syscfg = <&exti 0x60 0xff>;
			pins-are-numbered;

			gpioa: gpio@50002000 {
				gpio-controller;
				#gpio-cells = <2>;
				interrupt-controller;
				#interrupt-cells = <2>;
				reg = <0x0 0x400>;
				clocks = <&rcc GPIOA>;
				st,bank-name = "GPIOA";
				ngpios = <16>;
				gpio-ranges = <&pinctrl 0 0 16>;
			};

			gpiob: gpio@50003000 {
				gpio-controller;
				#gpio-cells = <2>;
				interrupt-controller;
				#interrupt-cells = <2>;
				reg = <0x1000 0x400>;
				clocks = <&rcc GPIOB>;
				st,bank-name = "GPIOB";
				ngpios = <16>;
				gpio-ranges = <&pinctrl 0 16 16>;
			};

			gpioc: gpio@50004000 {
				gpio-controller;
				#gpio-cells = <2>;
				interrupt-controller;
				#interrupt-cells = <2>;
				reg = <0x2000 0x400>;
				clocks = <&rcc GPIOC>;
				st,bank-name = "GPIOC";
				ngpios = <16>;
				gpio-ranges = <&pinctrl 0 32 16>;
			};

			gpiod: gpio@50005000 {
				gpio-controller;
				#gpio-cells = <2>;
				interrupt-controller;
				#interrupt-cells = <2>;
				reg = <0x3000 0x400>;
				clocks = <&rcc GPIOD>;
				st,bank-name = "GPIOD";
				ngpios = <16>;
				gpio-ranges = <&pinctrl 0 48 16>;
			};

			gpioe: gpio@50006000 {
				gpio-controller;
				#gpio-cells = <2>;
				interrupt-controller;
				#interrupt-cells = <2>;
				reg = <0x4000 0x400>;
				clocks = <&rcc GPIOE>;
				st,bank-name = "GPIOE";
				ngpios = <16>;
				gpio-ranges = <&pinctrl 0 64 16>;
			};

			gpiof: gpio@50007000 {
				gpio-controller;
				#gpio-cells = <2>;
				interrupt-controller;
				#interrupt-cells = <2>;
				reg = <0x5000 0x400>;
				clocks = <&rcc GPIOF>;
				st,bank-name = "GPIOF";
				ngpios = <16>;
				gpio-ranges = <&pinctrl 0 80 16>;
			};

			gpiog: gpio@50008000 {
				gpio-controller;
				#gpio-cells = <2>;
				interrupt-controller;
				#interrupt-cells = <2>;
				reg = <0x6000 0x400>;
				clocks = <&rcc GPIOG>;
				st,bank-name = "GPIOG";
				ngpios = <16>;
				gpio-ranges = <&pinctrl 0 96 16>;
			};

			gpioh: gpio@50009000 {
				gpio-controller;
				#gpio-cells = <2>;
				interrupt-controller;
				#interrupt-cells = <2>;
				reg = <0x7000 0x400>;
				clocks = <&rcc GPIOH>;
				st,bank-name = "GPIOH";
				ngpios = <15>;
				gpio-ranges = <&pinctrl 0 112 15>;
			};

			gpioi: gpio@5000a000 {
				gpio-controller;
				#gpio-cells = <2>;
				interrupt-controller;
				#interrupt-cells = <2>;
				reg = <0x8000 0x400>;
				clocks = <&rcc GPIOI>;
				st,bank-name = "GPIOI";
				ngpios = <8>;
				gpio-ranges = <&pinctrl 0 128 8>;
			};
		};
	};
};
